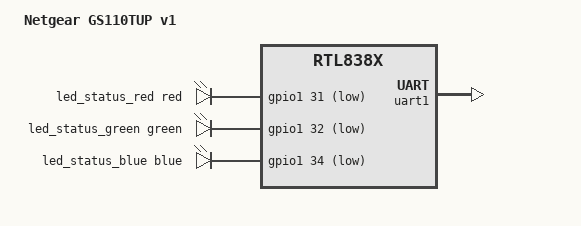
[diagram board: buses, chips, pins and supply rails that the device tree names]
// SPDX-License-Identifier: GPL-2.0-or-later

#include "rtl8380_netgear_gigabit.dtsi"
#include <dt-bindings/leds/common.h>

/ {
	compatible = "netgear,gs110tup-v1", "realtek,rtl838x-soc";
	model = "Netgear GS110TUP v1";

	aliases {
		led-boot = &led_status_green;
		led-failsafe = &led_status_red;
		led-running = &led_status_green;
		led-upgrade = &led_status_blue;
	};

	leds {
		compatible = "gpio-leds";

		led_status_red: led-0 {
			color = <LED_COLOR_ID_RED>;
			function = LED_FUNCTION_STATUS;
			gpios = <&gpio1 31 GPIO_ACTIVE_LOW>;
		};

		led_status_green: led-1 {
			color = <LED_COLOR_ID_GREEN>;
			function = LED_FUNCTION_STATUS;
			gpios = <&gpio1 32 GPIO_ACTIVE_LOW>;
		};

		led_status_blue: led-2 {
			color = <LED_COLOR_ID_BLUE>;
			function = LED_FUNCTION_STATUS;
			gpios = <&gpio1 34 GPIO_ACTIVE_LOW>;
		};
	};
};

&firmware {
	openwrt,ih-magic = <0x4e474720>;
};

&uart1 {
	status = "okay";
};

&mdio_bus0 {
	PHY_C22(16, 16)
};

&switch0 {
	ethernet-ports {
		SWITCH_PORT_SDS(16, 9, 2, 0, qsgmii)

		port@24 {
			reg = <24>;
			label = "lan10";
			pcs-handle = <&serdes4 0>;
			phy-mode = "1000base-x";
			managed = "in-band-status";
			/* i2c and gpios not yet identified */
		};
	};
};
